# GD32F527 register map
File version: 1.0
CPU: CM33 r0p1, little endian, MPU, FPU, 4 interrupt priority bits
Registers are 32-bit, read-write, reset 0x0 unless marked. A register's access mark holds for its fields unless they carry their own. Offsets are from the block's base; [hi:lo] are bit positions; {n}, {i} and the like mark numbered series.

## HS_HOST — USB on the go full speed host
Base 0x40040400
0x00 HCTL — host control register (HCTL)
  [2] SPDFSLS — Speed limited to FS and LS
0x04 HFT reset 0xBB80 — Host frame interval register
  [15:0] FRI — Frame interval
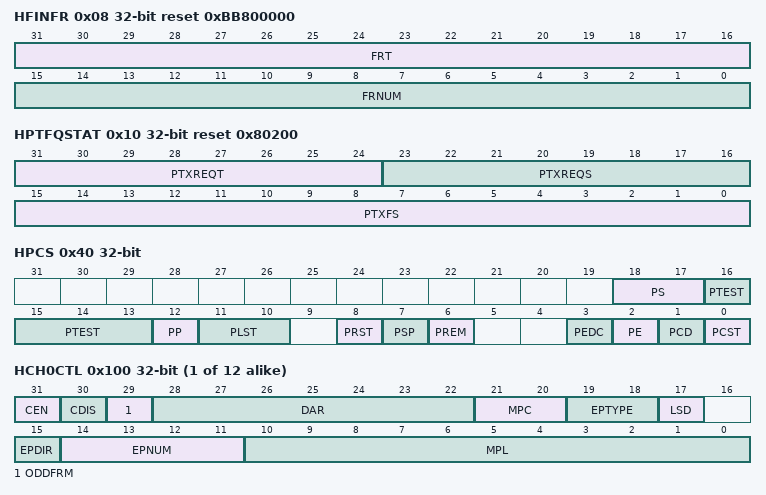
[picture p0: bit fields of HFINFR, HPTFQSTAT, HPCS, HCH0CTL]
0x08 HFINFR ro reset 0xBB800000 — host frame number/frame time remaining register (HFINFR)
  [31:16] FRT — Frame remaining time
  [15:0] FRNUM — Frame number
0x10 HPTFQSTAT ro reset 0x80200 — Host periodic transmit FIFO/queue status register (HPTFQSTAT)
  [31:24] PTXREQT — Top of the periodic transmit request queue
  [23:16] PTXREQS — Periodic Tx request queue space
  [15:0] PTXFS — Periodic transmit data FIFO space available
0x14 HACHINT ro — Host all channels interrupt register
  [11:0] HACHINT — Host all channel interrupts
0x18 HACHINTEN — host all channels interrupt mask register
  [11:0] CINTEN — Channel interrupt enable
0x40 HPCS access per field — host port control and status register (HPCS)
  [18:17] PS ro — Port speed
  [16:13] PTEST rw — Port Test control
  [12] PP rw — Port power
  [11:10] PLST ro — Port line status
  [8] PRST rw — Port reset
  [7] PSP rw — Port suspend
  [6] PREM rw — Port resume
  [3] PEDC rw — Port enable/disable change
  [2] PE rw — Port enable
  [1] PCD rw — Port connect detected
  [0] PCST ro — Port connect status
{0x100+0x20*i} HCH{i}CTL (i=0..11) — host channel-{i} control register (HCH{i}CTL)
  [31] CEN — Channel enable
  [30] CDIS — Channel disable
  [29] ODDFRM — Odd frame
  [28:22] DAR — Device address
  [21:20] MPC — Multiple packet count
  [19:18] EPTYPE — Endpoint type
  [17] LSD — Low-speed device
  [15] EPDIR — Endpoint direction
  [14:11] EPNUM — Endpoint number
  [10:0] MPL — Maximum packet size
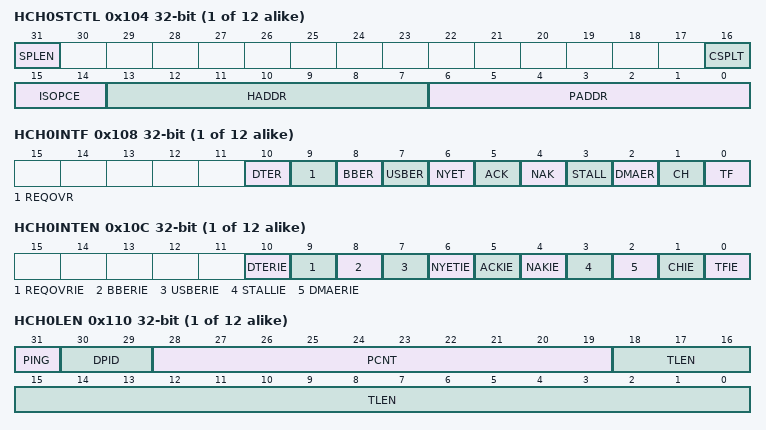
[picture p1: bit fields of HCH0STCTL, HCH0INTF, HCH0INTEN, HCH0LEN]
{0x104+0x20*i} HCH{i}STCTL (i=0..11) — host channel-{i} split transaction control register (HCH{i}STCTL)
  [31] SPLEN — Enable high speed split transaction
  [16] CSPLT — Complete split enable
  [15:14] ISOPCE — Isochronous OUT payload continuation encoding
  [13:7] HADDR — HUB address
  [6:0] PADDR — Port address
{0x108+0x20*i} HCH{i}INTF (i=0..11) — host channel-{i} interrupt flag register (HCH{i}INTF)
  [10] DTER — Data toggle error
  [9] REQOVR — Request queue overrun
  [8] BBER — Babble error
  [7] USBER — USB bus error
  [6] NYET
  [5] ACK — ACK response received/transmitted interrupt
  [4] NAK — NAK response received interrupt
  [3] STALL — STALL response received interrupt
  [2] DMAER — DMA Error
  [1] CH — Channel halted
  [0] TF — Transfer completed
{0x10C+0x20*i} HCH{i}INTEN (i=0..11) — host channel-{i} interrupt enable register (HCH{i}INTEN)
  [10] DTERIE — Data toggle error interrupt enable
  [9] REQOVRIE — request queue overrun interrupt enable
  [8] BBERIE — Babble error interrupt enable
  [7] USBERIE — USB bus error interrupt enable
  [6] NYETIE — NYET interrupt enable
  [5] ACKIE — ACK interrupt enable
  [4] NAKIE — NAK interrupt enable
  [3] STALLIE — STALL interrupt enable
  [2] DMAERIE — DMA error interrupt enable
  [1] CHIE — Channel halted interrupt enable
  [0] TFIE — Transfer finished interrupt enable
{0x110+0x20*i} HCH{i}LEN (i=0..11) — host channel-{i} transfer length register
  [31] PING — Ping token request
  [30:29] DPID — Data PID
  [28:19] PCNT — Packet count
  [18:0] TLEN — Transfer length
{0x114+0x20*i} HCH{i}DMAADDR (i=0..11) — host channel-{i} DMA address register
  [31:0] DMAADDR — DMA address

## FWDGT — Free watchdog timer
Base 0x40003000
0x00 FWDGT_CTL wo — Control register
  [15:0] CMD — Key value
0x04 FWDGT_PSC — Prescaler register
  [3:0] PSC — Free watchdog timer prescaler selection
0x08 FWDGT_RLD reset 0xFFF — Reload register
  [11:0] RLD — Free watchdog timer counter reload value
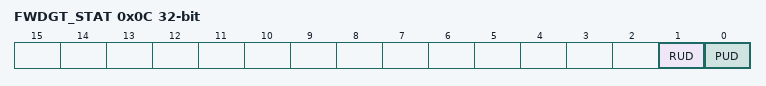
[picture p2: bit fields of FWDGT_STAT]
0x0C FWDGT_STAT ro — Status register
  [1] RUD — Free watchdog timer counter reload value update
  [0] PUD — Free watchdog timer prescaler value update

## WWDGT — Window watchdog timer
Base 0x40002C00
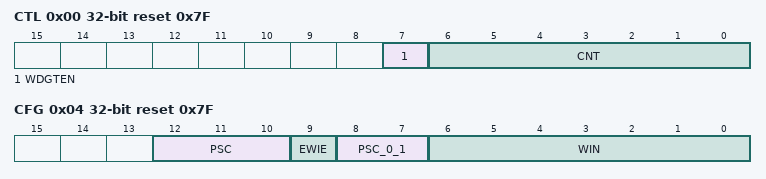
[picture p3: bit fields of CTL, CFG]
0x00 CTL reset 0x7F — Control register
  [7] WDGTEN — Start the window watchdog timer
  [6:0] CNT — The value of the watchdog timer counter
0x04 CFG reset 0x7F — Configuration register
  [12:10] PSC — High bit value of prescaler
  [9] EWIE — Early wakeup interrupt enable
  [8:7] PSC_0_1 — Low bit value of prescaler
  [6:0] WIN — The Window value
0x08 STAT — Status register
  [0] EWIF — Early wakeup interrupt flag
